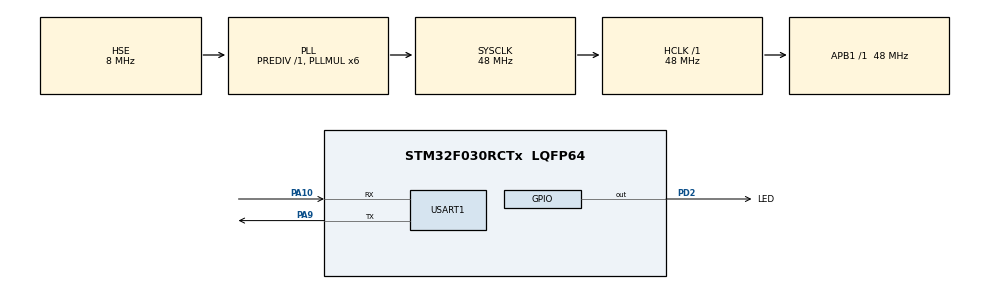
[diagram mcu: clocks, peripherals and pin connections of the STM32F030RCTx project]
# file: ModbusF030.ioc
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FREERTOS.Tasks01=defaultTask,24,128,StartDefaultTask,Default,NULL,Dynamic,NULL,NULL
Mcu.Family=STM32F0
Mcu.Name=STM32F030RCTx
Mcu.Package=LQFP64
NVIC.RCC_IRQn=true\:3\:0\:false\:false\:true\:true\:true\:false\:true
NVIC.TIM17_IRQn=true\:3\:0\:false\:false\:true\:false\:false\:true\:true
NVIC.TimeBase=TIM17_IRQn
NVIC.TimeBaseIP=TIM17
NVIC.USART1_IRQn=true\:3\:0\:false\:false\:true\:true\:true\:true\:true
PA10.Mode=Asynchronous
PA10.Signal=USART1_RX
PA13.Mode=Serial_Wire
PA13.Signal=SYS_SWDIO
PA14.Mode=Serial_Wire
PA14.Signal=SYS_SWCLK
PA9.Mode=Asynchronous
PA9.Signal=USART1_TX
PD2.GPIO_Label=LED
PD2.Signal=GPIO_Output
PF0-OSC_IN.Mode=HSE-External-Oscillator
PF0-OSC_IN.Signal=RCC_OSC_IN
PF1-OSC_OUT.Mode=HSE-External-Oscillator
PF1-OSC_OUT.Signal=RCC_OSC_OUT
ProjectManager.HeapSize=0x200
ProjectManager.StackSize=0x400
ProjectManager.TargetToolchain=STM32CubeIDE
RCC.AHBFreq_Value=48000000
RCC.APB1Freq_Value=48000000
RCC.APB1TimFreq_Value=48000000
RCC.HCLKFreq_Value=48000000
RCC.PLLMUL=RCC_PLL_MUL6
RCC.PLLSourceVirtual=RCC_PLLSOURCE_HSE
RCC.SYSCLKFreq_VALUE=48000000
RCC.SYSCLKSource=RCC_SYSCLKSOURCE_PLLCLK
USART1.VirtualMode-Asynchronous=VM_ASYNC
VP_FREERTOS_VS_CMSIS_V2.Mode=CMSIS_V2
VP_SYS_VS_tim17.Mode=TIM17
board=custom

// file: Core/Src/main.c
/* USER CODE BEGIN Header */
/**
  ******************************************************************************
  * @file           : main.c
  * @brief          : Main program body
  ******************************************************************************
  * @attention
  *
  * Copyright (c) 2024 STMicroelectronics.
  * All rights reserved.
  *
  * This software is licensed under terms that can be found in the LICENSE file
  * in the root directory of this software component.
  * If no LICENSE file comes with this software, it is provided AS-IS.
  *
  ******************************************************************************
  */
/* USER CODE END Header */
#include "main.h"
#include "cmsis_os.h"
#include "usart.h"
#include "gpio.h"

/* USER CODE BEGIN PV */
modbusHandler_t ModbusH;
uint16_t ModbusDATA[8];
/* USER CODE END PV */

void SystemClock_Config(void);
void MX_FREERTOS_Init(void);

int main(void)
{

  /* MCU Configuration--------------------------------------------------------*/

  /* Reset of all peripherals, Initializes the Flash interface and the Systick. */
  HAL_Init();

  /* Configure the system clock */
  SystemClock_Config();

  /* Initialize all configured peripherals */
  MX_GPIO_Init();
  MX_USART1_UART_Init();
  /* USER CODE BEGIN 2 */
  ModbusH.uModbusType = MB_SLAVE;
  ModbusH.port =  &huart1;
  ModbusH.u8id = 1; //Modbus slave ID
  ModbusH.u16timeOut = 1000;
  ModbusH.EN_Port = NULL;
  ModbusH.u16regs = ModbusDATA;
  ModbusH.u16regsize= sizeof(ModbusDATA)/sizeof(ModbusDATA[0]);
  ModbusH.xTypeHW = USART_HW;
  //Initialize Modbus library
  ModbusInit(&ModbusH);
  //Start capturing traffic on serial Port
  ModbusStart(&ModbusH);
  /* USER CODE END 2 */

  /* Init scheduler */
  osKernelInitialize();

  /* Call init function for freertos objects (in freertos.c) */
  MX_FREERTOS_Init();

  /* Start scheduler */
  osKernelStart();

  /* We should never get here as control is now taken by the scheduler */
  /* Infinite loop */
  while (1)
  {

  }
}

void SystemClock_Config(void)
{
  RCC_OscInitTypeDef RCC_OscInitStruct = {0};
  RCC_ClkInitTypeDef RCC_ClkInitStruct = {0};
  RCC_PeriphCLKInitTypeDef PeriphClkInit = {0};

  /** Initializes the RCC Oscillators according to the specified parameters
  * in the RCC_OscInitTypeDef structure.
  */
  RCC_OscInitStruct.OscillatorType = RCC_OSCILLATORTYPE_HSE;
  RCC_OscInitStruct.HSEState = RCC_HSE_ON;
  RCC_OscInitStruct.PLL.PLLState = RCC_PLL_ON;
  RCC_OscInitStruct.PLL.PLLSource = RCC_PLLSOURCE_HSE;
  RCC_OscInitStruct.PLL.PLLMUL = RCC_PLL_MUL6;
  RCC_OscInitStruct.PLL.PREDIV = RCC_PREDIV_DIV1;
  if (HAL_RCC_OscConfig(&RCC_OscInitStruct) != HAL_OK)
  {
    Error_Handler();
  }

  /** Initializes the CPU, AHB and APB buses clocks
  */
  RCC_ClkInitStruct.ClockType = RCC_CLOCKTYPE_HCLK|RCC_CLOCKTYPE_SYSCLK
                              |RCC_CLOCKTYPE_PCLK1;
  RCC_ClkInitStruct.SYSCLKSource = RCC_SYSCLKSOURCE_PLLCLK;
  RCC_ClkInitStruct.AHBCLKDivider = RCC_SYSCLK_DIV1;
  RCC_ClkInitStruct.APB1CLKDivider = RCC_HCLK_DIV1;

  if (HAL_RCC_ClockConfig(&RCC_ClkInitStruct, FLASH_LATENCY_1) != HAL_OK)
  {
    Error_Handler();
  }
  PeriphClkInit.PeriphClockSelection = RCC_PERIPHCLK_USART1;
  PeriphClkInit.Usart1ClockSelection = RCC_USART1CLKSOURCE_PCLK1;
  if (HAL_RCCEx_PeriphCLKConfig(&PeriphClkInit) != HAL_OK)
  {
    Error_Handler();
  }
}

void HAL_TIM_PeriodElapsedCallback(TIM_HandleTypeDef *htim)
{
  if (htim->Instance == TIM17) {
    HAL_IncTick();
  }
}

void Error_Handler(void)
{
  __disable_irq();
  while (1)
  {
  }
}

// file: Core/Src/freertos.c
/* USER CODE BEGIN Header */
/**
  ******************************************************************************
  * File Name          : freertos.c
  * Description        : Code for freertos applications
  ******************************************************************************
  * @attention
  *
  * Copyright (c) 2024 STMicroelectronics.
  * All rights reserved.
  *
  * This software is licensed under terms that can be found in the LICENSE file
  * in the root directory of this software component.
  * If no LICENSE file comes with this software, it is provided AS-IS.
  *
  ******************************************************************************
  */
/* USER CODE END Header */

#include "FreeRTOS.h"
#include "task.h"
#include "main.h"
#include "cmsis_os.h"

/* Definitions for defaultTask */
osThreadId_t defaultTaskHandle;
const osThreadAttr_t defaultTask_attributes = {
  .name = "defaultTask",
  .stack_size = 128 * 4,
  .priority = (osPriority_t) osPriorityNormal,
};

void StartDefaultTask(void *argument);

void MX_FREERTOS_Init(void); /* (MISRA C 2004 rule 8.1) */

void MX_FREERTOS_Init(void) {

  /* Create the thread(s) */
  /* creation of defaultTask */
  defaultTaskHandle = osThreadNew(StartDefaultTask, NULL, &defaultTask_attributes);

}

void StartDefaultTask(void *argument)
{
  /* USER CODE BEGIN StartDefaultTask */
  uint16_t delayCount = 0;
  /* Infinite loop */
  for(;;)
  {
    HAL_GPIO_TogglePin(LED_GPIO_Port, LED_Pin);

    /*
    slave address       01
    modbus function     06
    register address    00
    register value --> led delay times
    */
    if (ModbusDATA[0])
    {
        delayCount = ModbusDATA[0];
    }
    else
    {
        delayCount = 250;
    }

    osDelay(delayCount);
  }
  /* USER CODE END StartDefaultTask */
}
